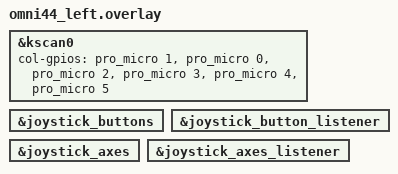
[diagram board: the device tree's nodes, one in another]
#include "omni44.dtsi"

&kscan0 {
    col-gpios
        = <&pro_micro 1 GPIO_ACTIVE_HIGH>
        , <&pro_micro 0 GPIO_ACTIVE_HIGH>
        , <&pro_micro 2 GPIO_ACTIVE_HIGH>
        , <&pro_micro 3 GPIO_ACTIVE_HIGH>
        , <&pro_micro 4 GPIO_ACTIVE_HIGH>
        , <&pro_micro 5 GPIO_ACTIVE_HIGH>
    ;
};

&joystick_buttons {
    status = "okay";
};

&joystick_button_listener {
    status = "okay";
};

&joystick_axes {
    status = "okay";
};

&joystick_axes_listener {
    status = "okay";
};
